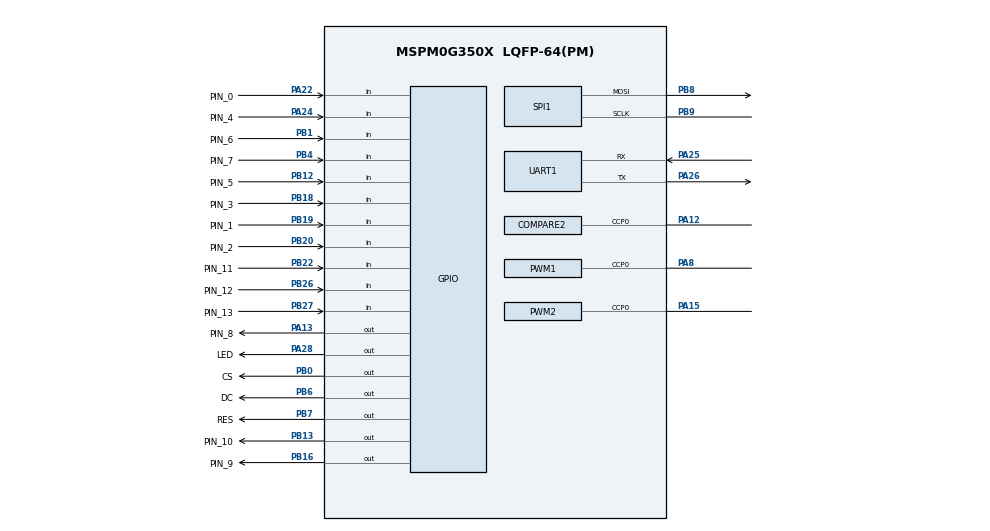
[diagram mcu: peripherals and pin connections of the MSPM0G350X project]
/**
 * @cliArgs --device "MSPM0G350X" --package "LQFP-64(PM)" --part "Default" --product "mspm0_sdk@1.20.01.06"
 * @versions {"tool":"1.19.0+3426"}
 */

/**
 * Import the modules used in this configuration.
 */
const ADC12    = scripting.addModule("/ti/driverlib/ADC12", {}, false);
const ADC121   = ADC12.addInstance();
const ADC122   = ADC12.addInstance();
const COMPARE  = scripting.addModule("/ti/driverlib/COMPARE", {}, false);
const COMPARE1 = COMPARE.addInstance();
const COMPARE2 = COMPARE.addInstance();
const GPIO     = scripting.addModule("/ti/driverlib/GPIO", {}, false);
const GPIO1    = GPIO.addInstance();
const GPIO2    = GPIO.addInstance();
const GPIO3    = GPIO.addInstance();
const GPIO4    = GPIO.addInstance();
const GPIO5    = GPIO.addInstance();
const GPIO6    = GPIO.addInstance();
const GPIO7    = GPIO.addInstance();
const GPIO8    = GPIO.addInstance();
const GPIO9    = GPIO.addInstance();
const GPIO10   = GPIO.addInstance();
const GPIO11   = GPIO.addInstance();
const GPIO12   = GPIO.addInstance();
const GPIO13   = GPIO.addInstance();
const GPIO14   = GPIO.addInstance();
const GPIO15   = GPIO.addInstance();
const GPIO16   = GPIO.addInstance();
const PWM      = scripting.addModule("/ti/driverlib/PWM", {}, false);
const PWM1     = PWM.addInstance();
const PWM2     = PWM.addInstance();
const PWM3     = PWM.addInstance();
const SPI      = scripting.addModule("/ti/driverlib/SPI", {}, false);
const SPI1     = SPI.addInstance();
const SYSCTL   = scripting.addModule("/ti/driverlib/SYSCTL");
const TIMER    = scripting.addModule("/ti/driverlib/TIMER", {}, false);
const TIMER1   = TIMER.addInstance();
const UART     = scripting.addModule("/ti/driverlib/UART", {}, false);
const UART1    = UART.addInstance();

/**
 * Write custom configuration values to the imported modules.
 */
const divider6       = system.clockTree["PLL_CLK2X_DIV"];
divider6.divideValue = 4;

const divider7       = system.clockTree["PLL_PDIV"];
divider7.divideValue = 2;

const divider9       = system.clockTree["UDIV"];
divider9.divideValue = 2;

const multiplier2         = system.clockTree["PLL_QDIV"];
multiplier2.multiplyValue = 10;

const mux8       = system.clockTree["HSCLKMUX"];
mux8.inputSelect = "HSCLKMUX_SYSPLL2X";

ADC121.$name               = "ADC12_0";
ADC121.sampClkSrc          = "DL_ADC12_CLOCK_ULPCLK";
ADC121.sampClkDiv          = "DL_ADC12_CLOCK_DIVIDE_4";
ADC121.adcMem0chansel      = "DL_ADC12_INPUT_CHAN_2";
ADC121.powerDownMode       = "DL_ADC12_POWER_DOWN_MODE_MANUAL";
ADC121.sampleTime0         = "125us";
ADC121.peripheral.$assign  = "ADC1";
ADC121.adcPin2Config.$name = "ti_driverlib_gpio_GPIOPinGeneric8";

ADC122.$name                 = "ADC12_1";
ADC122.sampClkSrc            = "DL_ADC12_CLOCK_ULPCLK";
ADC122.samplingOperationMode = "sequence";
ADC122.endAdd                = 1;
ADC122.adcMem1chansel        = "DL_ADC12_INPUT_CHAN_5";
ADC122.powerDownMode         = "DL_ADC12_POWER_DOWN_MODE_MANUAL";
ADC122.sampleTime0           = "62.5ns";
ADC122.adcPin0Config.$name   = "ti_driverlib_gpio_GPIOPinGeneric10";
ADC122.adcPin5Config.$name   = "ti_driverlib_gpio_GPIOPinGeneric11";

const Board = scripting.addModule("/ti/driverlib/Board", {}, false);

COMPARE1.$name                                    = "COMPARE_0";
COMPARE1.timerPeriod                              = 65535;
COMPARE1.interrupts                               = ["ZERO"];
COMPARE1.timerClkDiv                              = 2;
COMPARE1.peripheral.$assign                       = "TIMG6";
COMPARE1.peripheral.ccp0Pin.$assignAllowConflicts = "PB2";
COMPARE1.ccp0PinConfig.$name                      = "ti_driverlib_gpio_GPIOPinGeneric6";

COMPARE2.$name                      = "COMPARE_1";
COMPARE2.timerPeriod                = 65535;
COMPARE2.interrupts                 = ["ZERO"];
COMPARE2.peripheral.ccp0Pin.$assign = "PA12";
COMPARE2.ccp0PinConfig.$name        = "ti_driverlib_gpio_GPIOPinGeneric7";

GPIO1.$name                              = "A_0";
GPIO1.associatedPins[0].$name            = "PIN_0";
GPIO1.associatedPins[0].initialValue     = "SET";
GPIO1.associatedPins[0].direction        = "INPUT";
GPIO1.associatedPins[0].ioStructure      = "SD";
GPIO1.associatedPins[0].internalResistor = "PULL_UP";
GPIO1.associatedPins[0].pin.$assign      = "PA22";

GPIO2.$name                              = "A_1";
GPIO2.associatedPins[0].$name            = "PIN_1";
GPIO2.associatedPins[0].direction        = "INPUT";
GPIO2.associatedPins[0].ioStructure      = "SD";
GPIO2.associatedPins[0].internalResistor = "PULL_UP";
GPIO2.associatedPins[0].pin.$assign      = "PB19";

GPIO3.$name                              = "A_2";
GPIO3.associatedPins[0].$name            = "PIN_2";
GPIO3.associatedPins[0].direction        = "INPUT";
GPIO3.associatedPins[0].ioStructure      = "SD";
GPIO3.associatedPins[0].internalResistor = "PULL_UP";
GPIO3.associatedPins[0].pin.$assign      = "PB20";

GPIO4.$name                              = "A_3";
GPIO4.associatedPins[0].$name            = "PIN_3";
GPIO4.associatedPins[0].direction        = "INPUT";
GPIO4.associatedPins[0].ioStructure      = "SD";
GPIO4.associatedPins[0].internalResistor = "PULL_UP";
GPIO4.associatedPins[0].pin.$assign      = "PB18";

GPIO5.$name                              = "A_4";
GPIO5.associatedPins[0].$name            = "PIN_4";
GPIO5.associatedPins[0].direction        = "INPUT";
GPIO5.associatedPins[0].ioStructure      = "SD";
GPIO5.associatedPins[0].internalResistor = "PULL_UP";
GPIO5.associatedPins[0].pin.$assign      = "PA24";

GPIO6.$name                              = "A_5";
GPIO6.associatedPins[0].$name            = "PIN_5";
GPIO6.associatedPins[0].direction        = "INPUT";
GPIO6.associatedPins[0].ioStructure      = "SD";
GPIO6.associatedPins[0].internalResistor = "PULL_UP";
GPIO6.associatedPins[0].pin.$assign      = "PB12";

GPIO7.$name                              = "A_6";
GPIO7.port                               = "PORTB";
GPIO7.associatedPins[0].$name            = "PIN_6";
GPIO7.associatedPins[0].direction        = "INPUT";
GPIO7.associatedPins[0].ioStructure      = "SD";
GPIO7.associatedPins[0].internalResistor = "PULL_UP";
GPIO7.associatedPins[0].pin.$assign      = "PB1";

GPIO8.$name                              = "A_7";
GPIO8.associatedPins[0].$name            = "PIN_7";
GPIO8.associatedPins[0].direction        = "INPUT";
GPIO8.associatedPins[0].ioStructure      = "SD";
GPIO8.associatedPins[0].internalResistor = "PULL_UP";
GPIO8.associatedPins[0].pin.$assign      = "PB4";

GPIO9.$name                         = "LEDON";
GPIO9.associatedPins[0].$name       = "PIN_8";
GPIO9.associatedPins[0].pin.$assign = "PA13";

GPIO10.$name                          = "GPIO_TFT";
GPIO10.associatedPins.create(3);
GPIO10.associatedPins[0].initialValue = "SET";
GPIO10.associatedPins[0].$name        = "RES";
GPIO10.associatedPins[0].pin.$assign  = "PB7";
GPIO10.associatedPins[1].$name        = "DC";
GPIO10.associatedPins[1].initialValue = "SET";
GPIO10.associatedPins[1].pin.$assign  = "PB6";
GPIO10.associatedPins[2].$name        = "CS";
GPIO10.associatedPins[2].initialValue = "SET";
GPIO10.associatedPins[2].pin.$assign  = "PB0";

GPIO11.$name                         = "dir_L";
GPIO11.associatedPins[0].$name       = "PIN_9";
GPIO11.associatedPins[0].pin.$assign = "PB16";

GPIO12.$name                         = "dir_R";
GPIO12.associatedPins[0].$name       = "PIN_10";
GPIO12.associatedPins[0].pin.$assign = "PB13";

GPIO13.$name                              = "GPIO";
GPIO13.associatedPins[0].$name            = "LED";
GPIO13.associatedPins[0].ioStructure      = "HD";
GPIO13.associatedPins[0].internalResistor = "PULL_UP";
GPIO13.associatedPins[0].pin.$assign      = "PA28";

GPIO14.$name                              = "add";
GPIO14.associatedPins[0].$name            = "PIN_11";
GPIO14.associatedPins[0].direction        = "INPUT";
GPIO14.associatedPins[0].ioStructure      = "SD";
GPIO14.associatedPins[0].internalResistor = "PULL_UP";
GPIO14.associatedPins[0].pin.$assign      = "PB22";

GPIO15.$name                              = "sub";
GPIO15.associatedPins[0].$name            = "PIN_12";
GPIO15.associatedPins[0].direction        = "INPUT";
GPIO15.associatedPins[0].ioStructure      = "SD";
GPIO15.associatedPins[0].internalResistor = "PULL_UP";
GPIO15.associatedPins[0].pin.$assign      = "PB26";

GPIO16.$name                              = "next";
GPIO16.associatedPins[0].$name            = "PIN_13";
GPIO16.associatedPins[0].direction        = "INPUT";
GPIO16.associatedPins[0].ioStructure      = "SD";
GPIO16.associatedPins[0].internalResistor = "PULL_UP";
GPIO16.associatedPins[0].pin.$assign      = "PB27";

PWM1.$name                      = "PWM_0";
PWM1.ccIndex                    = [0];
PWM1.timerCount                 = 4001;
PWM1.peripheral.$assign         = "TIMA0";
PWM1.peripheral.ccp0Pin.$assign = "PA8";
PWM1.PWM_CHANNEL_0.$name        = "ti_driverlib_pwm_PWMTimerCC0";
PWM1.PWM_CHANNEL_0.dutyCycle    = 50;
PWM1.PWM_CHANNEL_0.invert       = true;
PWM1.ccp0PinConfig.$name        = "ti_driverlib_gpio_GPIOPinGeneric2";

PWM2.$name                      = "PWM_1";
PWM2.ccIndex                    = [0];
PWM2.timerCount                 = 4001;
PWM2.peripheral.ccp0Pin.$assign = "PA15";
PWM2.PWM_CHANNEL_0.$name        = "ti_driverlib_pwm_PWMTimerCC1";
PWM2.PWM_CHANNEL_0.ccValue      = 2000;
PWM2.PWM_CHANNEL_0.dutyCycle    = 50;
PWM2.PWM_CHANNEL_0.invert       = true;
PWM2.ccp0PinConfig.$name        = "ti_driverlib_gpio_GPIOPinGeneric3";

PWM3.$name                                    = "PWM_Buzzer";
PWM3.clockDivider                             = 2;
PWM3.timerCount                               = 40000;
PWM3.ccIndex                                  = [0];
PWM3.peripheral.ccp0Pin.$assignAllowConflicts = "PB15";
PWM3.PWM_CHANNEL_0.$name                      = "ti_driverlib_pwm_PWMTimerCC2";
PWM3.PWM_CHANNEL_0.dutyCycle                  = 50;
PWM3.PWM_CHANNEL_0.invert                     = true;
PWM3.ccp0PinConfig.direction                  = scripting.forceWrite("OUTPUT");
PWM3.ccp0PinConfig.hideOutputInversion        = scripting.forceWrite(false);
PWM3.ccp0PinConfig.onlyInternalResistor       = scripting.forceWrite(false);
PWM3.ccp0PinConfig.passedPeripheralType       = scripting.forceWrite("Digital");
PWM3.ccp0PinConfig.$name                      = "ti_driverlib_gpio_GPIOPinGeneric9";

SPI1.$name                      = "SPI_0";
SPI1.targetBitRate              = 16000000;
SPI1.spiClkDiv                  = "2";
SPI1.frameFormat                = "MOTO3";
SPI1.direction                  = "PICO";
SPI1.peripheral.$assign         = "SPI1";
SPI1.peripheral.sclkPin.$assign = "PB9";
SPI1.peripheral.mosiPin.$assign = "PB8";
SPI1.sclkPinConfig.$name        = "ti_driverlib_gpio_GPIOPinGeneric4";
SPI1.mosiPinConfig.$name        = "ti_driverlib_gpio_GPIOPinGeneric5";

SYSCTL.forceDefaultClkConfig = true;
SYSCTL.clockTreeEn           = true;

TIMER1.$name            = "TIMER_0";
TIMER1.timerMode        = "PERIODIC";
TIMER1.timerPeriod      = "100 ms";
TIMER1.timerClkDiv      = 2;
TIMER1.timerClkPrescale = 100;
TIMER1.interrupts       = ["ZERO"];

UART1.$name                    = "UART_0";
UART1.targetBaudRate           = 115200;
UART1.enabledInterrupts        = ["RX"];
UART1.interruptPriority        = "1";
UART1.peripheral.rxPin.$assign = "PA25";
UART1.peripheral.txPin.$assign = "PA26";
UART1.txPinConfig.$name        = "ti_driverlib_gpio_GPIOPinGeneric0";
UART1.rxPinConfig.$name        = "ti_driverlib_gpio_GPIOPinGeneric1";

/**
 * Pinmux solution for unlocked pins/peripherals. This ensures that minor changes to the automatic solver in a future
 * version of the tool will not impact the pinmux you originally saw.  These lines can be completely deleted in order to
 * re-solve from scratch.
 */
ADC121.peripheral.adcPin2.$suggestSolution = "PA17";
ADC122.peripheral.$suggestSolution         = "ADC0";
ADC122.peripheral.adcPin0.$suggestSolution = "PA27";
ADC122.peripheral.adcPin5.$suggestSolution = "PB24";
Board.peripheral.$suggestSolution          = "DEBUGSS";
Board.peripheral.swclkPin.$suggestSolution = "PA20";
Board.peripheral.swdioPin.$suggestSolution = "PA19";
COMPARE2.peripheral.$suggestSolution       = "TIMG0";
PWM2.peripheral.$suggestSolution           = "TIMA1";
PWM3.peripheral.$suggestSolution           = "TIMG8";
TIMER1.peripheral.$suggestSolution         = "TIMG7";
UART1.peripheral.$suggestSolution          = "UART3";
